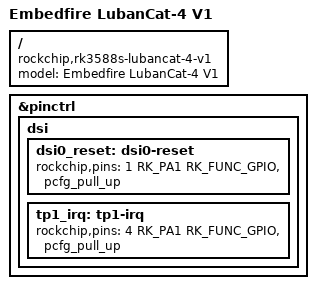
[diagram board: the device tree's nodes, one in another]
// SPDX-License-Identifier: (GPL-2.0+ OR MIT)
/*
 * Copyright (c) 2021 Rockchip Electronics Co., Ltd.
 * Copyright (c) 2023 EmbedFire <embedfire@embedfire.com>
 */

/dts-v1/;

#include "rk3588s-lubancat-4.dts"

/ {
	model = "Embedfire LubanCat-4 V1";
	compatible = "rockchip,rk3588s-lubancat-4-v1", "rockchip,rk3588";
};

&pinctrl{
	dsi {
		dsi0_reset: dsi0-reset {
			rockchip,pins = <1 RK_PA1 RK_FUNC_GPIO &pcfg_pull_up>;
		};

		tp1_irq: tp1-irq {
			rockchip,pins = <4 RK_PA1 RK_FUNC_GPIO &pcfg_pull_up>;
		};
	};
};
